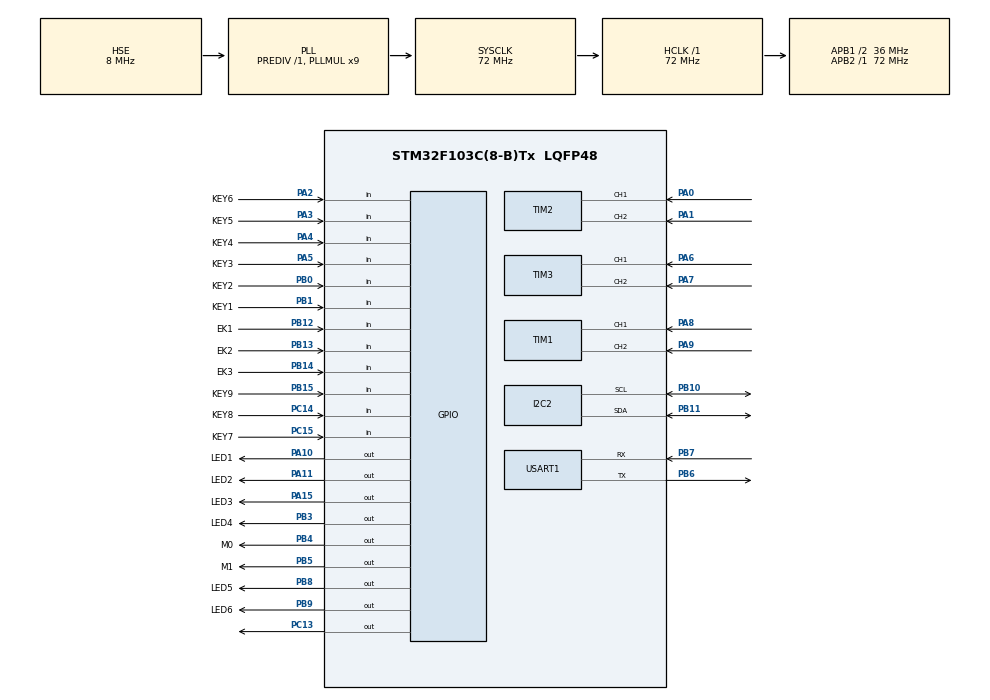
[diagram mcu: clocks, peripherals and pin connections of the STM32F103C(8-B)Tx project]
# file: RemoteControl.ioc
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Dma.Request0=USART1_RX
Dma.Request1=USART1_TX
Dma.USART1_RX.0.Direction=DMA_PERIPH_TO_MEMORY
Dma.USART1_RX.0.Instance=DMA1_Channel5
Dma.USART1_RX.0.MemDataAlignment=DMA_MDATAALIGN_BYTE
Dma.USART1_RX.0.MemInc=DMA_MINC_ENABLE
Dma.USART1_RX.0.Mode=DMA_NORMAL
Dma.USART1_RX.0.PeriphDataAlignment=DMA_PDATAALIGN_BYTE
Dma.USART1_RX.0.PeriphInc=DMA_PINC_DISABLE
Dma.USART1_RX.0.Priority=DMA_PRIORITY_LOW
Dma.USART1_TX.1.Direction=DMA_MEMORY_TO_PERIPH
Dma.USART1_TX.1.Instance=DMA1_Channel4
Dma.USART1_TX.1.MemDataAlignment=DMA_MDATAALIGN_BYTE
Dma.USART1_TX.1.MemInc=DMA_MINC_ENABLE
Dma.USART1_TX.1.Mode=DMA_NORMAL
Dma.USART1_TX.1.PeriphDataAlignment=DMA_PDATAALIGN_BYTE
Dma.USART1_TX.1.PeriphInc=DMA_PINC_DISABLE
Dma.USART1_TX.1.Priority=DMA_PRIORITY_LOW
FREERTOS.BinarySemaphores01=UART_RX_BS,Static,UART_RX_BSControlBlock,Available
FREERTOS.CountingSemaphores01=UART_TX_CS,2,Static,UART_TX_CSControlBlock,0
FREERTOS.Queues01=KEY_CMD_Q,16,App_Key_EventPacket_t,0,Static,KEY_CMD_QBuffer,KEY_CMD_QControlBlock;UART_RX_Q,16,uint8_t,0,Static,UART_RX_QBuffer,UART_RX_QControlBlock;UART_TX_Q,16,APP_TxFrame_t,0,Static,UART_TX_QBuffer,UART_TX_QControlBlock
FREERTOS.Tasks01=defaultTask,24,64,StartDefaultTask,Default,NULL,Static,defaultTaskBuffer,defaultTaskControlBlock;KEY_Debounce_T,55,128,Task_KEY_Debounce,As weak,NULL,Static,KEY_Debounce_TBuffer,KEY_Debounce_TControlBlock;KEY_CMD_T,39,256,TASK_KEY_CMD,As weak,NULL,Static,KEY_CMD_TBuffer,KEY_CMD_TControlBlock;UART_RX_T,47,256,Task_UART_RX,As weak,NULL,Static,UART_RX_TBuffer,UART_RX_TControlBlock;UART_TX_T,54,128,Task_UART_TX,As weak,NULL,Static,UART_TX_TBuffer,UART_TX_TControlBlock;UART_RX_CMD,38,128,Task_UART_RX_CMD,As weak,NULL,Static,UART_RX_CMDBuffer,UART_RX_CMDControlBlock;OLED_T,15,128,Task_OLED,As weak,NULL,Static,OLED_TBuffer,OLED_TControlBlock
FREERTOS.configMINIMAL_STACK_SIZE=64
FREERTOS.configTOTAL_HEAP_SIZE=256
I2C2.I2C_Mode=I2C_Fast
Mcu.Family=STM32F1
Mcu.Name=STM32F103C(8-B)Tx
Mcu.Package=LQFP48
NVIC.DMA1_Channel4_IRQn=true\:5\:0\:false\:false\:true\:true\:false\:true\:true
NVIC.DMA1_Channel5_IRQn=true\:5\:0\:false\:false\:true\:true\:false\:true\:true
NVIC.PriorityGroup=NVIC_PRIORITYGROUP_4
NVIC.TIM4_IRQn=true\:15\:0\:false\:false\:true\:false\:false\:true\:true
NVIC.TimeBase=TIM4_IRQn
NVIC.TimeBaseIP=TIM4
NVIC.USART1_IRQn=true\:5\:0\:false\:false\:true\:true\:true\:true\:true
PA0-WKUP.Signal=S_TIM2_CH1_ETR
PA1.Signal=S_TIM2_CH2
PA10.GPIO_Label=LED1
PA10.GPIO_ModeDefaultOutputPP=GPIO_MODE_OUTPUT_PP
PA10.GPIO_PuPd=GPIO_PULLDOWN
PA10.PinState=GPIO_PIN_RESET
PA10.Signal=GPIO_Output
PA11.GPIO_Label=LED2
PA11.GPIO_ModeDefaultOutputPP=GPIO_MODE_OUTPUT_PP
PA11.GPIO_PuPd=GPIO_PULLDOWN
PA11.PinState=GPIO_PIN_RESET
PA11.Signal=GPIO_Output
PA13.Mode=Serial_Wire
PA13.Signal=SYS_JTMS-SWDIO
PA14.Mode=Serial_Wire
PA14.Signal=SYS_JTCK-SWCLK
PA15.GPIO_Label=LED3
PA15.GPIO_ModeDefaultOutputPP=GPIO_MODE_OUTPUT_PP
PA15.GPIO_PuPd=GPIO_PULLDOWN
PA15.PinState=GPIO_PIN_RESET
PA15.Signal=GPIO_Output
PA2.GPIO_Label=KEY6
PA2.GPIO_Mode=GPIO_MODE_INPUT
PA2.GPIO_PuPd=GPIO_PULLUP
PA2.Signal=GPIO_Input
PA3.GPIO_Label=KEY5
PA3.GPIO_Mode=GPIO_MODE_INPUT
PA3.GPIO_PuPd=GPIO_PULLUP
PA3.Signal=GPIO_Input
PA4.GPIO_Label=KEY4
PA4.GPIO_Mode=GPIO_MODE_INPUT
PA4.GPIO_PuPd=GPIO_PULLUP
PA4.Signal=GPIO_Input
PA5.GPIO_Label=KEY3
PA5.GPIO_Mode=GPIO_MODE_INPUT
PA5.GPIO_PuPd=GPIO_PULLUP
PA5.Signal=GPIO_Input
PA6.Signal=S_TIM3_CH1
PA7.Signal=S_TIM3_CH2
PA8.Signal=S_TIM1_CH1
PA9.Signal=S_TIM1_CH2
PB0.GPIO_Label=KEY2
PB0.GPIO_Mode=GPIO_MODE_INPUT
PB0.GPIO_PuPd=GPIO_PULLUP
PB0.Signal=GPIO_Input
PB1.GPIO_Label=KEY1
PB1.GPIO_Mode=GPIO_MODE_INPUT
PB1.GPIO_PuPd=GPIO_PULLUP
PB1.Signal=GPIO_Input
PB10.Mode=I2C
PB10.Signal=I2C2_SCL
PB11.Mode=I2C
PB11.Signal=I2C2_SDA
PB12.GPIO_Label=EK1
PB12.GPIO_Mode=GPIO_MODE_INPUT
PB12.GPIO_PuPd=GPIO_PULLUP
PB12.Signal=GPIO_Input
PB13.GPIO_Label=EK2
PB13.GPIO_Mode=GPIO_MODE_INPUT
PB13.GPIO_PuPd=GPIO_PULLUP
PB13.Signal=GPIO_Input
PB14.GPIO_Label=EK3
PB14.GPIO_Mode=GPIO_MODE_INPUT
PB14.GPIO_PuPd=GPIO_PULLUP
PB14.Signal=GPIO_Input
PB15.GPIO_Label=KEY9
PB15.GPIO_Mode=GPIO_MODE_INPUT
PB15.GPIO_PuPd=GPIO_PULLUP
PB15.Signal=GPIO_Input
PB3.GPIO_Label=LED4
PB3.GPIO_ModeDefaultOutputPP=GPIO_MODE_OUTPUT_PP
PB3.GPIO_PuPd=GPIO_PULLDOWN
PB3.PinState=GPIO_PIN_RESET
PB3.Signal=GPIO_Output
PB4.GPIO_Label=M0
PB4.GPIO_ModeDefaultOutputPP=GPIO_MODE_OUTPUT_PP
PB4.GPIO_PuPd=GPIO_PULLDOWN
PB4.PinState=GPIO_PIN_RESET
PB4.Signal=GPIO_Output
PB5.GPIO_Label=M1
PB5.GPIO_ModeDefaultOutputPP=GPIO_MODE_OUTPUT_PP
PB5.GPIO_PuPd=GPIO_PULLDOWN
PB5.PinState=GPIO_PIN_RESET
PB5.Signal=GPIO_Output
PB6.Mode=Asynchronous
PB6.Signal=USART1_TX
PB7.Mode=Asynchronous
PB7.Signal=USART1_RX
PB8.GPIO_Label=LED5
PB8.GPIO_ModeDefaultOutputPP=GPIO_MODE_OUTPUT_PP
PB8.GPIO_PuPd=GPIO_PULLDOWN
PB8.PinState=GPIO_PIN_RESET
PB8.Signal=GPIO_Output
PB9.GPIO_Label=LED6
PB9.GPIO_ModeDefaultOutputPP=GPIO_MODE_OUTPUT_PP
PB9.GPIO_PuPd=GPIO_PULLDOWN
PB9.PinState=GPIO_PIN_RESET
PB9.Signal=GPIO_Output
PC13-TAMPER-RTC.PinState=GPIO_PIN_SET
PC13-TAMPER-RTC.Signal=GPIO_Output
PC14-OSC32_IN.GPIO_Label=KEY8
PC14-OSC32_IN.GPIO_Mode=GPIO_MODE_INPUT
PC14-OSC32_IN.GPIO_PuPd=GPIO_PULLUP
PC14-OSC32_IN.Signal=GPIO_Input
PC15-OSC32_OUT.GPIO_Label=KEY7
PC15-OSC32_OUT.GPIO_Mode=GPIO_MODE_INPUT
PC15-OSC32_OUT.GPIO_PuPd=GPIO_PULLUP
PC15-OSC32_OUT.Signal=GPIO_Input
PD0-OSC_IN.Mode=HSE-External-Oscillator
PD0-OSC_IN.Signal=RCC_OSC_IN
PD1-OSC_OUT.Mode=HSE-External-Oscillator
PD1-OSC_OUT.Signal=RCC_OSC_OUT
ProjectManager.HeapSize=0x200
ProjectManager.StackSize=0x400
ProjectManager.TargetToolchain=CMake
RCC.AHBFreq_Value=72000000
RCC.APB1CLKDivider=RCC_HCLK_DIV2
RCC.APB1Freq_Value=36000000
RCC.APB1TimFreq_Value=72000000
RCC.APB2Freq_Value=72000000
RCC.APB2TimFreq_Value=72000000
RCC.HCLKFreq_Value=72000000
RCC.PLLMUL=RCC_PLL_MUL9
RCC.PLLSourceVirtual=RCC_PLLSOURCE_HSE
RCC.SYSCLKFreq_VALUE=72000000
RCC.SYSCLKSource=RCC_SYSCLKSOURCE_PLLCLK
RCC.USBFreq_Value=72000000
SH.S_TIM1_CH1.0=TIM1_CH1,Encoder_Interface
SH.S_TIM1_CH2.0=TIM1_CH2,Encoder_Interface
SH.S_TIM2_CH1_ETR.0=TIM2_CH1,Encoder_Interface
SH.S_TIM2_CH2.0=TIM2_CH2,Encoder_Interface
SH.S_TIM3_CH1.0=TIM3_CH1,Encoder_Interface
SH.S_TIM3_CH2.0=TIM3_CH2,Encoder_Interface
TIM1.EncoderMode=TIM_ENCODERMODE_TI12
TIM2.EncoderMode=TIM_ENCODERMODE_TI12
TIM3.EncoderMode=TIM_ENCODERMODE_TI12
USART1.VirtualMode=VM_ASYNC
VP_FREERTOS_VS_CMSIS_V2.Mode=CMSIS_V2
VP_SYS_VS_tim4.Mode=TIM4
board=custom

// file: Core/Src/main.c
/* USER CODE BEGIN Header */
/**
  ******************************************************************************
  * @file           : main.c
  * @brief          : Main program body
  ******************************************************************************
  * @attention
  *
  * Copyright (c) 2026 STMicroelectronics.
  * All rights reserved.
  *
  * This software is licensed under terms that can be found in the LICENSE file
  * in the root directory of this software component.
  * If no LICENSE file comes with this software, it is provided AS-IS.
  *
  ******************************************************************************
  */
/* USER CODE END Header */
#include "main.h"
#include "cmsis_os.h"
#include "dma.h"
#include "i2c.h"
#include "tim.h"
#include "usart.h"
#include "gpio.h"

void SystemClock_Config(void);
void MX_FREERTOS_Init(void);

int main(void)
{

  /* MCU Configuration--------------------------------------------------------*/

  /* Reset of all peripherals, Initializes the Flash interface and the Systick. */
  HAL_Init();

  /* Configure the system clock */
  SystemClock_Config();

  /* Initialize all configured peripherals */
  MX_GPIO_Init();
  MX_DMA_Init();
  MX_I2C2_Init();
  MX_TIM1_Init();
  MX_TIM2_Init();
  MX_TIM3_Init();
  MX_USART1_UART_Init();

  /* Init scheduler */
  osKernelInitialize();  /* Call init function for freertos objects (in cmsis_os2.c) */
  MX_FREERTOS_Init();

  /* Start scheduler */
  osKernelStart();

  /* We should never get here as control is now taken by the scheduler */

  /* Infinite loop */
  while (1)
  {

  }
}

void SystemClock_Config(void)
{
  RCC_OscInitTypeDef RCC_OscInitStruct = {0};
  RCC_ClkInitTypeDef RCC_ClkInitStruct = {0};

  /** Initializes the RCC Oscillators according to the specified parameters
  * in the RCC_OscInitTypeDef structure.
  */
  RCC_OscInitStruct.OscillatorType = RCC_OSCILLATORTYPE_HSE;
  RCC_OscInitStruct.HSEState = RCC_HSE_ON;
  RCC_OscInitStruct.HSEPredivValue = RCC_HSE_PREDIV_DIV1;
  RCC_OscInitStruct.HSIState = RCC_HSI_ON;
  RCC_OscInitStruct.PLL.PLLState = RCC_PLL_ON;
  RCC_OscInitStruct.PLL.PLLSource = RCC_PLLSOURCE_HSE;
  RCC_OscInitStruct.PLL.PLLMUL = RCC_PLL_MUL9;
  if (HAL_RCC_OscConfig(&RCC_OscInitStruct) != HAL_OK)
  {
    Error_Handler();
  }

  /** Initializes the CPU, AHB and APB buses clocks
  */
  RCC_ClkInitStruct.ClockType = RCC_CLOCKTYPE_HCLK|RCC_CLOCKTYPE_SYSCLK
                              |RCC_CLOCKTYPE_PCLK1|RCC_CLOCKTYPE_PCLK2;
  RCC_ClkInitStruct.SYSCLKSource = RCC_SYSCLKSOURCE_PLLCLK;
  RCC_ClkInitStruct.AHBCLKDivider = RCC_SYSCLK_DIV1;
  RCC_ClkInitStruct.APB1CLKDivider = RCC_HCLK_DIV2;
  RCC_ClkInitStruct.APB2CLKDivider = RCC_HCLK_DIV1;

  if (HAL_RCC_ClockConfig(&RCC_ClkInitStruct, FLASH_LATENCY_2) != HAL_OK)
  {
    Error_Handler();
  }
}

void HAL_TIM_PeriodElapsedCallback(TIM_HandleTypeDef *htim)
{
  if (htim->Instance == TIM4)
  {
    HAL_IncTick();
  }
}

void Error_Handler(void)
{
  __disable_irq();
  while (1)
  {
  }
}

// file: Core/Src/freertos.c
/* USER CODE BEGIN Header */
/**
  ******************************************************************************
  * File Name          : freertos.c
  * Description        : Code for freertos applications
  ******************************************************************************
  * @attention
  *
  * Copyright (c) 2026 STMicroelectronics.
  * All rights reserved.
  *
  * This software is licensed under terms that can be found in the LICENSE file
  * in the root directory of this software component.
  * If no LICENSE file comes with this software, it is provided AS-IS.
  *
  ******************************************************************************
  */
/* USER CODE END Header */

#include "FreeRTOS.h"
#include "task.h"
#include "main.h"
#include "cmsis_os.h"

/* USER CODE BEGIN Includes */
#include "app_key.h"
#include "app_uart.h"
/* USER CODE END Includes */

typedef StaticTask_t osStaticThreadDef_t;
typedef StaticQueue_t osStaticMessageQDef_t;
typedef StaticSemaphore_t osStaticSemaphoreDef_t;

/* Definitions for defaultTask */
osThreadId_t defaultTaskHandle;
uint32_t defaultTaskBuffer[ 64 ];
osStaticThreadDef_t defaultTaskControlBlock;
const osThreadAttr_t defaultTask_attributes = {
  .name = "defaultTask",
  .cb_mem = &defaultTaskControlBlock,
  .cb_size = sizeof(defaultTaskControlBlock),
  .stack_mem = &defaultTaskBuffer[0],
  .stack_size = sizeof(defaultTaskBuffer),
  .priority = (osPriority_t) osPriorityNormal,
};
/* Definitions for KEY_Debounce_T */
osThreadId_t KEY_Debounce_THandle;
uint32_t KEY_Debounce_TBuffer[ 128 ];
osStaticThreadDef_t KEY_Debounce_TControlBlock;
const osThreadAttr_t KEY_Debounce_T_attributes = {
  .name = "KEY_Debounce_T",
  .cb_mem = &KEY_Debounce_TControlBlock,
  .cb_size = sizeof(KEY_Debounce_TControlBlock),
  .stack_mem = &KEY_Debounce_TBuffer[0],
  .stack_size = sizeof(KEY_Debounce_TBuffer),
  .priority = (osPriority_t) osPriorityRealtime7,
};
/* Definitions for KEY_CMD_T */
osThreadId_t KEY_CMD_THandle;
uint32_t KEY_CMD_TBuffer[ 256 ];
osStaticThreadDef_t KEY_CMD_TControlBlock;
const osThreadAttr_t KEY_CMD_T_attributes = {
  .name = "KEY_CMD_T",
  .cb_mem = &KEY_CMD_TControlBlock,
  .cb_size = sizeof(KEY_CMD_TControlBlock),
  .stack_mem = &KEY_CMD_TBuffer[0],
  .stack_size = sizeof(KEY_CMD_TBuffer),
  .priority = (osPriority_t) osPriorityAboveNormal7,
};
/* Definitions for UART_RX_T */
osThreadId_t UART_RX_THandle;
uint32_t UART_RX_TBuffer[ 256 ];
osStaticThreadDef_t UART_RX_TControlBlock;
const osThreadAttr_t UART_RX_T_attributes = {
  .name = "UART_RX_T",
  .cb_mem = &UART_RX_TControlBlock,
  .cb_size = sizeof(UART_RX_TControlBlock),
  .stack_mem = &UART_RX_TBuffer[0],
  .stack_size = sizeof(UART_RX_TBuffer),
  .priority = (osPriority_t) osPriorityHigh7,
};
/* Definitions for UART_TX_T */
osThreadId_t UART_TX_THandle;
uint32_t UART_TX_TBuffer[ 128 ];
osStaticThreadDef_t UART_TX_TControlBlock;
const osThreadAttr_t UART_TX_T_attributes = {
  .name = "UART_TX_T",
  .cb_mem = &UART_TX_TControlBlock,
  .cb_size = sizeof(UART_TX_TControlBlock),
  .stack_mem = &UART_TX_TBuffer[0],
  .stack_size = sizeof(UART_TX_TBuffer),
  .priority = (osPriority_t) osPriorityRealtime6,
};
/* Definitions for UART_RX_CMD */
osThreadId_t UART_RX_CMDHandle;
uint32_t UART_RX_CMDBuffer[ 128 ];
osStaticThreadDef_t UART_RX_CMDControlBlock;
const osThreadAttr_t UART_RX_CMD_attributes = {
  .name = "UART_RX_CMD",
  .cb_mem = &UART_RX_CMDControlBlock,
  .cb_size = sizeof(UART_RX_CMDControlBlock),
  .stack_mem = &UART_RX_CMDBuffer[0],
  .stack_size = sizeof(UART_RX_CMDBuffer),
  .priority = (osPriority_t) osPriorityAboveNormal6,
};
/* Definitions for OLED_T */
osThreadId_t OLED_THandle;
uint32_t OLED_TBuffer[ 128 ];
osStaticThreadDef_t OLED_TControlBlock;
const osThreadAttr_t OLED_T_attributes = {
  .name = "OLED_T",
  .cb_mem = &OLED_TControlBlock,
  .cb_size = sizeof(OLED_TControlBlock),
  .stack_mem = &OLED_TBuffer[0],
  .stack_size = sizeof(OLED_TBuffer),
  .priority = (osPriority_t) osPriorityLow7,
};
/* Definitions for KEY_CMD_Q */
osMessageQueueId_t KEY_CMD_QHandle;
uint8_t KEY_CMD_QBuffer[ 16 * sizeof( App_Key_EventPacket_t ) ];
osStaticMessageQDef_t KEY_CMD_QControlBlock;
const osMessageQueueAttr_t KEY_CMD_Q_attributes = {
  .name = "KEY_CMD_Q",
  .cb_mem = &KEY_CMD_QControlBlock,
  .cb_size = sizeof(KEY_CMD_QControlBlock),
  .mq_mem = &KEY_CMD_QBuffer,
  .mq_size = sizeof(KEY_CMD_QBuffer)
};
/* Definitions for UART_RX_Q */
osMessageQueueId_t UART_RX_QHandle;
uint8_t UART_RX_QBuffer[ 16 * sizeof( uint8_t ) ];
osStaticMessageQDef_t UART_RX_QControlBlock;
const osMessageQueueAttr_t UART_RX_Q_attributes = {
  .name = "UART_RX_Q",
  .cb_mem = &UART_RX_QControlBlock,
  .cb_size = sizeof(UART_RX_QControlBlock),
  .mq_mem = &UART_RX_QBuffer,
  .mq_size = sizeof(UART_RX_QBuffer)
};
/* Definitions for UART_TX_Q */
osMessageQueueId_t UART_TX_QHandle;
uint8_t UART_TX_QBuffer[ 16 * sizeof( APP_TxFrame_t ) ];
osStaticMessageQDef_t UART_TX_QControlBlock;
const osMessageQueueAttr_t UART_TX_Q_attributes = {
  .name = "UART_TX_Q",
  .cb_mem = &UART_TX_QControlBlock,
  .cb_size = sizeof(UART_TX_QControlBlock),
  .mq_mem = &UART_TX_QBuffer,
  .mq_size = sizeof(UART_TX_QBuffer)
};
/* Definitions for UART_RX_BS */
osSemaphoreId_t UART_RX_BSHandle;
osStaticSemaphoreDef_t UART_RX_BSControlBlock;
const osSemaphoreAttr_t UART_RX_BS_attributes = {
  .name = "UART_RX_BS",
  .cb_mem = &UART_RX_BSControlBlock,
  .cb_size = sizeof(UART_RX_BSControlBlock),
};
/* Definitions for UART_TX_CS */
osSemaphoreId_t UART_TX_CSHandle;
osStaticSemaphoreDef_t UART_TX_CSControlBlock;
const osSemaphoreAttr_t UART_TX_CS_attributes = {
  .name = "UART_TX_CS",
  .cb_mem = &UART_TX_CSControlBlock,
  .cb_size = sizeof(UART_TX_CSControlBlock),
};

void StartDefaultTask(void *argument);
void Task_KEY_Debounce(void *argument);
void TASK_KEY_CMD(void *argument);
void Task_UART_RX(void *argument);
void Task_UART_TX(void *argument);
void Task_UART_RX_CMD(void *argument);
void Task_OLED(void *argument);

void MX_FREERTOS_Init(void); /* (MISRA C 2004 rule 8.1) */

void MX_FREERTOS_Init(void) {

  /* Create the semaphores(s) */
  /* creation of UART_RX_BS */
  UART_RX_BSHandle = osSemaphoreNew(1, 1, &UART_RX_BS_attributes);

  /* creation of UART_TX_CS */
  UART_TX_CSHandle = osSemaphoreNew(2, 0, &UART_TX_CS_attributes);

  /* Create the queue(s) */
  /* creation of KEY_CMD_Q */
  KEY_CMD_QHandle = osMessageQueueNew (16, sizeof(App_Key_EventPacket_t), &KEY_CMD_Q_attributes);

  /* creation of UART_RX_Q */
  UART_RX_QHandle = osMessageQueueNew (16, sizeof(uint8_t), &UART_RX_Q_attributes);

  /* creation of UART_TX_Q */
  UART_TX_QHandle = osMessageQueueNew (16, sizeof(APP_TxFrame_t), &UART_TX_Q_attributes);

  /* Create the thread(s) */
  /* creation of defaultTask */
  defaultTaskHandle = osThreadNew(StartDefaultTask, NULL, &defaultTask_attributes);

  /* creation of KEY_Debounce_T */
  KEY_Debounce_THandle = osThreadNew(Task_KEY_Debounce, NULL, &KEY_Debounce_T_attributes);

  /* creation of KEY_CMD_T */
  KEY_CMD_THandle = osThreadNew(TASK_KEY_CMD, NULL, &KEY_CMD_T_attributes);

  /* creation of UART_RX_T */
  UART_RX_THandle = osThreadNew(Task_UART_RX, NULL, &UART_RX_T_attributes);

  /* creation of UART_TX_T */
  UART_TX_THandle = osThreadNew(Task_UART_TX, NULL, &UART_TX_T_attributes);

  /* creation of UART_RX_CMD */
  UART_RX_CMDHandle = osThreadNew(Task_UART_RX_CMD, NULL, &UART_RX_CMD_attributes);

  /* creation of OLED_T */
  OLED_THandle = osThreadNew(Task_OLED, NULL, &OLED_T_attributes);

}

void StartDefaultTask(void *argument)
{
  for(;;)
  {
    osDelay(1);
  }
}

__weak void Task_KEY_Debounce(void *argument)
{
  for(;;)
  {
    osDelay(1);
  }
}

__weak void TASK_KEY_CMD(void *argument)
{
  for(;;)
  {
    osDelay(1);
  }
}

__weak void Task_UART_RX(void *argument)
{
  for(;;)
  {
    osDelay(1);
  }
}

__weak void Task_UART_TX(void *argument)
{
  for(;;)
  {
    osDelay(1);
  }
}

__weak void Task_UART_RX_CMD(void *argument)
{
  for(;;)
  {
    osDelay(1);
  }
}

__weak void Task_OLED(void *argument)
{
  for(;;)
  {
    osDelay(1);
  }
}
